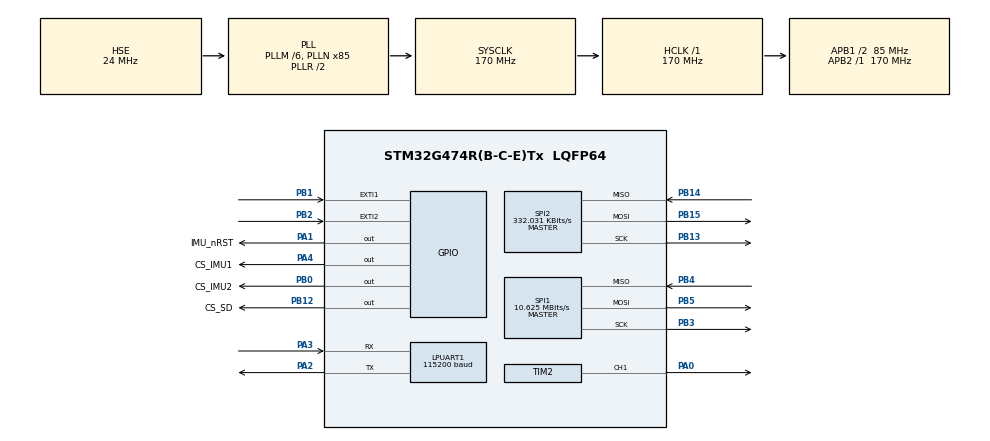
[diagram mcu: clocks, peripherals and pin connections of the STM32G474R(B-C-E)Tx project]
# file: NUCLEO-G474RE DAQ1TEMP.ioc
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Dma.Request0=SPI1_RX
Dma.Request1=SPI2_TX
Dma.Request2=SPI2_RX
Dma.Request3=SPI1_TX
Dma.SPI1_RX.0.Direction=DMA_PERIPH_TO_MEMORY
Dma.SPI1_RX.0.EventEnable=DISABLE
Dma.SPI1_RX.0.Instance=DMA1_Channel1
Dma.SPI1_RX.0.MemDataAlignment=DMA_MDATAALIGN_BYTE
Dma.SPI1_RX.0.MemInc=DMA_MINC_ENABLE
Dma.SPI1_RX.0.Mode=DMA_NORMAL
Dma.SPI1_RX.0.PeriphDataAlignment=DMA_PDATAALIGN_BYTE
Dma.SPI1_RX.0.PeriphInc=DMA_PINC_DISABLE
Dma.SPI1_RX.0.Polarity=HAL_DMAMUX_REQ_GEN_RISING
Dma.SPI1_RX.0.Priority=DMA_PRIORITY_LOW
Dma.SPI1_RX.0.RequestNumber=1
Dma.SPI1_RX.0.SignalID=NONE
Dma.SPI1_RX.0.SyncEnable=DISABLE
Dma.SPI1_RX.0.SyncPolarity=HAL_DMAMUX_SYNC_NO_EVENT
Dma.SPI1_RX.0.SyncRequestNumber=1
Dma.SPI1_RX.0.SyncSignalID=NONE
Dma.SPI1_TX.3.Direction=DMA_MEMORY_TO_PERIPH
Dma.SPI1_TX.3.EventEnable=DISABLE
Dma.SPI1_TX.3.Instance=DMA1_Channel2
Dma.SPI1_TX.3.MemDataAlignment=DMA_MDATAALIGN_BYTE
Dma.SPI1_TX.3.MemInc=DMA_MINC_ENABLE
Dma.SPI1_TX.3.Mode=DMA_NORMAL
Dma.SPI1_TX.3.PeriphDataAlignment=DMA_PDATAALIGN_BYTE
Dma.SPI1_TX.3.PeriphInc=DMA_PINC_DISABLE
Dma.SPI1_TX.3.Polarity=HAL_DMAMUX_REQ_GEN_RISING
Dma.SPI1_TX.3.Priority=DMA_PRIORITY_LOW
Dma.SPI1_TX.3.RequestNumber=1
Dma.SPI1_TX.3.SignalID=NONE
Dma.SPI1_TX.3.SyncEnable=DISABLE
Dma.SPI1_TX.3.SyncPolarity=HAL_DMAMUX_SYNC_NO_EVENT
Dma.SPI1_TX.3.SyncRequestNumber=1
Dma.SPI1_TX.3.SyncSignalID=NONE
Dma.SPI2_RX.2.Direction=DMA_PERIPH_TO_MEMORY
Dma.SPI2_RX.2.EventEnable=DISABLE
Dma.SPI2_RX.2.Instance=DMA1_Channel4
Dma.SPI2_RX.2.MemDataAlignment=DMA_MDATAALIGN_BYTE
Dma.SPI2_RX.2.MemInc=DMA_MINC_ENABLE
Dma.SPI2_RX.2.Mode=DMA_NORMAL
Dma.SPI2_RX.2.PeriphDataAlignment=DMA_PDATAALIGN_BYTE
Dma.SPI2_RX.2.PeriphInc=DMA_PINC_DISABLE
Dma.SPI2_RX.2.Polarity=HAL_DMAMUX_REQ_GEN_RISING
Dma.SPI2_RX.2.Priority=DMA_PRIORITY_LOW
Dma.SPI2_RX.2.RequestNumber=1
Dma.SPI2_RX.2.SignalID=NONE
Dma.SPI2_RX.2.SyncEnable=DISABLE
Dma.SPI2_RX.2.SyncPolarity=HAL_DMAMUX_SYNC_NO_EVENT
Dma.SPI2_RX.2.SyncRequestNumber=1
Dma.SPI2_RX.2.SyncSignalID=NONE
Dma.SPI2_TX.1.Direction=DMA_MEMORY_TO_PERIPH
Dma.SPI2_TX.1.EventEnable=DISABLE
Dma.SPI2_TX.1.Instance=DMA1_Channel3
Dma.SPI2_TX.1.MemDataAlignment=DMA_MDATAALIGN_BYTE
Dma.SPI2_TX.1.MemInc=DMA_MINC_ENABLE
Dma.SPI2_TX.1.Mode=DMA_NORMAL
Dma.SPI2_TX.1.PeriphDataAlignment=DMA_PDATAALIGN_BYTE
Dma.SPI2_TX.1.PeriphInc=DMA_PINC_DISABLE
Dma.SPI2_TX.1.Polarity=HAL_DMAMUX_REQ_GEN_RISING
Dma.SPI2_TX.1.Priority=DMA_PRIORITY_LOW
Dma.SPI2_TX.1.RequestNumber=1
Dma.SPI2_TX.1.SignalID=NONE
Dma.SPI2_TX.1.SyncEnable=DISABLE
Dma.SPI2_TX.1.SyncPolarity=HAL_DMAMUX_SYNC_NO_EVENT
Dma.SPI2_TX.1.SyncRequestNumber=1
Dma.SPI2_TX.1.SyncSignalID=NONE
FATFS._USE_LFN=0
LPUART1.BaudRate=115200
Mcu.Family=STM32G4
Mcu.Name=STM32G474R(B-C-E)Tx
Mcu.Package=LQFP64
NUCLEO-G474RE.BUTTON=1
NUCLEO-G474RE.LD2=true
NUCLEO-G474RE.VCP=false
NVIC.DMA1_Channel1_IRQn=true\:2\:0\:true\:false\:true\:false\:true\:true
NVIC.DMA1_Channel2_IRQn=true\:2\:0\:true\:false\:true\:false\:true\:true
NVIC.DMA1_Channel3_IRQn=true\:4\:0\:true\:false\:true\:false\:true\:true
NVIC.DMA1_Channel4_IRQn=true\:4\:0\:true\:false\:true\:false\:true\:true
NVIC.EXTI15_10_IRQn=true\:5\:0\:true\:false\:true\:false\:true\:true
NVIC.PriorityGroup=NVIC_PRIORITYGROUP_4
NVIC.TIM6_DAC_IRQn=true\:12\:0\:true\:false\:true\:true\:true\:true
PA0.Signal=S_TIM2_CH1
PA1.GPIO_Label=IMU_nRST
PA1.GPIO_ModeDefaultOutputPP=GPIO_MODE_OUTPUT_OD
PA1.GPIO_PuPd=GPIO_NOPULL
PA1.PinState=GPIO_PIN_SET
PA1.Signal=GPIO_Output
PA13.GPIO_Label=T_SWDIO
PA13.Mode=Serial_Wire
PA13.Signal=SYS_JTMS-SWDIO
PA14.GPIO_Label=T_SWCLK
PA14.Mode=Serial_Wire
PA14.Signal=SYS_JTCK-SWCLK
PA2.Mode=Asynchronous
PA2.Signal=LPUART1_TX
PA3.Mode=Asynchronous
PA3.Signal=LPUART1_RX
PA4.GPIO_Label=CS_IMU1
PA4.GPIO_ModeDefaultOutputPP=GPIO_MODE_OUTPUT_PP
PA4.GPIO_Speed=GPIO_SPEED_FREQ_VERY_HIGH
PA4.PinState=GPIO_PIN_SET
PA4.Signal=GPIO_Output
PB0.GPIO_Label=CS_IMU2
PB0.GPIO_Speed=GPIO_SPEED_FREQ_VERY_HIGH
PB0.PinState=GPIO_PIN_SET
PB0.Signal=GPIO_Output
PB1.Signal=GPXTI1
PB12.GPIO_Label=CS_SD
PB12.GPIO_Speed=GPIO_SPEED_FREQ_VERY_HIGH
PB12.PinState=GPIO_PIN_SET
PB12.Signal=GPIO_Output
PB13.Mode=Full_Duplex_Master
PB13.Signal=SPI2_SCK
PB14.Mode=Full_Duplex_Master
PB14.Signal=SPI2_MISO
PB15.Mode=Full_Duplex_Master
PB15.Signal=SPI2_MOSI
PB2.Signal=GPXTI2
PB3.Mode=Full_Duplex_Master
PB3.Signal=SPI1_SCK
PB4.Mode=Full_Duplex_Master
PB4.Signal=SPI1_MISO
PB5.Mode=Full_Duplex_Master
PB5.Signal=SPI1_MOSI
PC14-OSC32_IN.GPIO_Label=RCC_OSC32_IN
PC14-OSC32_IN.Mode=LSE-External-Oscillator
PC14-OSC32_IN.Signal=RCC_OSC32_IN
PC15-OSC32_OUT.GPIO_Label=RCC_OSC32_OUT
PC15-OSC32_OUT.Mode=LSE-External-Oscillator
PC15-OSC32_OUT.Signal=RCC_OSC32_OUT
PF0-OSC_IN.GPIO_Label=RCC_OSC_IN
PF0-OSC_IN.Mode=HSE-External-Oscillator
PF0-OSC_IN.Signal=RCC_OSC_IN
PF1-OSC_OUT.GPIO_Label=RCC_OSC_OUT
PF1-OSC_OUT.Mode=HSE-External-Oscillator
PF1-OSC_OUT.Signal=RCC_OSC_OUT
ProjectManager.HeapSize=0x200
ProjectManager.StackSize=0x400
ProjectManager.TargetToolchain=STM32CubeIDE
RCC.ADC12Freq_Value=170000000
RCC.ADC345Freq_Value=170000000
RCC.AHBFreq_Value=170000000
RCC.APB1CLKDivider=RCC_HCLK_DIV2
RCC.APB1Freq_Value=85000000
RCC.APB1TimFreq_Value=170000000
RCC.APB2Freq_Value=170000000
RCC.APB2TimFreq_Value=170000000
RCC.CortexFreq_Value=170000000
RCC.EXTERNAL_CLOCK_VALUE=12288000
RCC.HCLKFreq_Value=170000000
RCC.HSE_VALUE=24000000
RCC.HSI48_VALUE=48000000
RCC.HSI_VALUE=16000000
RCC.PLLM=RCC_PLLM_DIV6
RCC.PLLN=85
RCC.PLLSourceVirtual=RCC_PLLSOURCE_HSE
RCC.RTCClockSelection=RCC_RTCCLKSOURCE_LSE
RCC.SYSCLKFreq_VALUE=170000000
RCC.SYSCLKSource=RCC_SYSCLKSOURCE_PLLCLK
RCC.USBFreq_Value=170000000
RCC.VCOOutputFreq_Value=340000000
SH.S_TIM2_CH1.0=TIM2_CH1,PWM Generation1 CH1
SPI1.BaudRatePrescaler=SPI_BAUDRATEPRESCALER_16
SPI1.CLKPhase=SPI_PHASE_2EDGE
SPI1.CLKPolarity=SPI_POLARITY_HIGH
SPI1.CalculateBaudRate=10.625 MBits/s
SPI1.DataSize=SPI_DATASIZE_8BIT
SPI1.Direction=SPI_DIRECTION_2LINES
SPI1.Mode=SPI_MODE_MASTER
SPI1.VirtualType=VM_MASTER
SPI2.BaudRatePrescaler=SPI_BAUDRATEPRESCALER_256
SPI2.CalculateBaudRate=332.031 KBits/s
SPI2.DataSize=SPI_DATASIZE_8BIT
SPI2.Direction=SPI_DIRECTION_2LINES
SPI2.Mode=SPI_MODE_MASTER
SPI2.VirtualType=VM_MASTER
TIM2.Channel-PWM\ Generation1\ CH1=TIM_CHANNEL_1
TIM2.PeriodNoDither=999
TIM2.Prescaler=169
TIM2.PulseNoDither_1=500
TIM6.PeriodNoDither=4999
TIM6.Prescaler=16999
VP_FATFS_VS_Generic.Mode=User_defined
VP_NUCLEO-G474RE_VS_BSP_COMMON.Mode=COMMON
VP_SYS_VS_DBSignals.Mode=DisableDeadBatterySignals
VP_TIM2_VS_ClockSourceINT.Mode=Internal
VP_TIM6_VS_ClockSourceINT.Mode=Enable_Timer
board=NUCLEO-G474RE

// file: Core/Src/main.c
/* USER CODE BEGIN Header */
/**
  ******************************************************************************
  * @file           : main.c
  * @brief          : Main program body
  ******************************************************************************
  * @attention
  *
  * Copyright (c) 2026 STMicroelectronics.
  * All rights reserved.
  *
  * This software is licensed under terms that can be found in the LICENSE file
  * in the root directory of this software component.
  * If no LICENSE file comes with this software, it is provided AS-IS.
  *
  ******************************************************************************
  */
/* USER CODE END Header */
#include "main.h"
#include "dma.h"
#include "app_fatfs.h"
#include "usart.h"
#include "spi.h"
#include "tim.h"
#include "gpio.h"

/* USER CODE BEGIN Includes */
#include "state_machine.h"
#include "datalogger.h"
#include "timestamp.h"
#include <stdio.h>
/* USER CODE END Includes */

void SystemClock_Config(void);

int main(void)
{

  /* MCU Configuration--------------------------------------------------------*/

  /* Reset of all peripherals, Initializes the Flash interface and the Systick. */
  HAL_Init();

  /* Configure the system clock */
  SystemClock_Config();

  /* Initialize all configured peripherals */
  MX_GPIO_Init();
  MX_DMA_Init();
  MX_SPI1_Init();
  MX_SPI2_Init();
  MX_TIM2_Init();
  MX_TIM6_Init();
  MX_LPUART1_UART_Init();
  if (MX_FATFS_Init() != APP_OK) {
    Error_Handler();
  }
  /* USER CODE BEGIN 2 */
  /* BSP LED must be initialised before StateMachine_Init() uses it.
     The generated BSP_LED_Init call below is idempotent, so this is safe. */
  BSP_LED_Init(LED_GREEN);
  StateMachine_Init();
  /* USER CODE END 2 */

  /* Initialize led */
  BSP_LED_Init(LED_GREEN);

  /* Initialize USER push-button, will be used to trigger an interrupt each time it's pressed.*/
  BSP_PB_Init(BUTTON_USER, BUTTON_MODE_EXTI);

  /* Infinite loop */
  /* USER CODE BEGIN WHILE */
  while (1)
  {
    StateMachine_Process();
    DataLogger_MainLoopProcess();
    /* USER CODE END WHILE */

  }
}

void SystemClock_Config(void)
{
  RCC_OscInitTypeDef RCC_OscInitStruct = {0};
  RCC_ClkInitTypeDef RCC_ClkInitStruct = {0};

  /** Configure the main internal regulator output voltage
  */
  HAL_PWREx_ControlVoltageScaling(PWR_REGULATOR_VOLTAGE_SCALE1_BOOST);

  /** Initializes the RCC Oscillators according to the specified parameters
  * in the RCC_OscInitTypeDef structure.
  */
  RCC_OscInitStruct.OscillatorType = RCC_OSCILLATORTYPE_HSE;
  RCC_OscInitStruct.HSEState = RCC_HSE_ON;
  RCC_OscInitStruct.PLL.PLLState = RCC_PLL_ON;
  RCC_OscInitStruct.PLL.PLLSource = RCC_PLLSOURCE_HSE;
  RCC_OscInitStruct.PLL.PLLM = RCC_PLLM_DIV6;
  RCC_OscInitStruct.PLL.PLLN = 85;
  RCC_OscInitStruct.PLL.PLLP = RCC_PLLP_DIV2;
  RCC_OscInitStruct.PLL.PLLQ = RCC_PLLQ_DIV2;
  RCC_OscInitStruct.PLL.PLLR = RCC_PLLR_DIV2;
  if (HAL_RCC_OscConfig(&RCC_OscInitStruct) != HAL_OK)
  {
    Error_Handler();
  }

  /** Initializes the CPU, AHB and APB buses clocks
  */
  RCC_ClkInitStruct.ClockType = RCC_CLOCKTYPE_HCLK|RCC_CLOCKTYPE_SYSCLK
                              |RCC_CLOCKTYPE_PCLK1|RCC_CLOCKTYPE_PCLK2;
  RCC_ClkInitStruct.SYSCLKSource = RCC_SYSCLKSOURCE_PLLCLK;
  RCC_ClkInitStruct.AHBCLKDivider = RCC_SYSCLK_DIV1;
  RCC_ClkInitStruct.APB1CLKDivider = RCC_HCLK_DIV2;
  RCC_ClkInitStruct.APB2CLKDivider = RCC_HCLK_DIV1;

  if (HAL_RCC_ClockConfig(&RCC_ClkInitStruct, FLASH_LATENCY_4) != HAL_OK)
  {
    Error_Handler();
  }
}

/* USER CODE BEGIN 4 */
/* HAL callbacks are implemented in datalogger.c and state_machine.c */
/* USER CODE END 4 */

void Error_Handler(void)
{
  __disable_irq();
  while (1)
  {
  }
}
